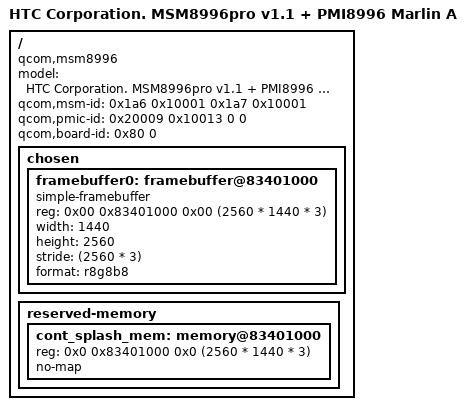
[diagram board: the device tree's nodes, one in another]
// SPDX-License-Identifier: BSD-3-Clause

/dts-v1/;

#include "msm8996.dtsi"
#include "pm8994.dtsi"
#include "pmi8994.dtsi"

/ {
	model = "HTC Corporation. MSM8996pro v1.1 + PMI8996 Marlin A";
	compatible = "qcom,msm8996";
	qcom,msm-id = <0x1a6 0x10001 0x1a7 0x10001>;
	qcom,pmic-id = <0x20009 0x10013 0 0>;
	qcom,board-id = <0x80 0>;

	chosen {
		#address-cells = <2>;
		#size-cells = <2>;
		ranges;

		framebuffer0: framebuffer@83401000 {
			compatible = "simple-framebuffer";
			reg = <0x00 0x83401000 0x00 (2560 * 1440 * 3)>;
			width = <1440>;
			height = <2560>;
			stride = <(2560 * 3)>;
			format = "r8g8b8";
		};
	};

	reserved-memory {
		cont_splash_mem: memory@83401000 {
			reg = <0x0 0x83401000 0x0 (2560 * 1440 * 3)>;
			no-map;
		};
	};
};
